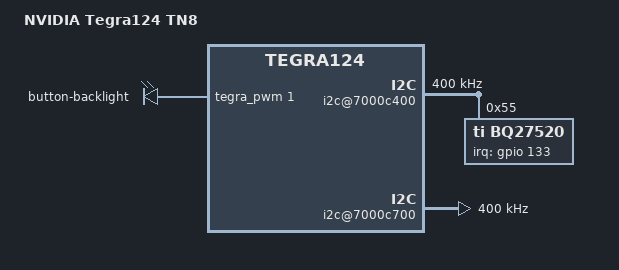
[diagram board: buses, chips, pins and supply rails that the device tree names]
/*
 * arch/arm/boot/dts/tegra124-mocha.dts
 *
 * Copyright (c) 2018, Smoke team.  All rights reserved.
 *
 * This program is free software; you can redistribute it and/or modify
 * it under the terms of the GNU General Public License as published by
 * the Free Software Foundation; either version 2 of the License, or
 * (at your option) any later version.
 *
 * This program is distributed in the hope that it will be useful, but WITHOUT
 * ANY WARRANTY; without even the implied warranty of MERCHANTABILITY or
 * FITNESS FOR A PARTICULAR PURPOSE.  See the GNU General Public License for
 * more details.
 *
 * You should have received a copy of the GNU General Public License along
 * with this program; if not, write to the Free Software Foundation, Inc.,
 * 51 Franklin Street, Fifth Floor, Boston, MA  02110-1301, USA.
 */
/dts-v1/;

#include "tegra124-tn8.dtsi"
#include "tegra124-platforms/tegra124-tn8-emc-e1922-1100-a00.dtsi"
#include "tegra124-platforms/tegra124-mocha-gpio-e1780.dtsi"
#include "tegra124-platforms/tegra124-mocha-keys-e1780.dtsi"
#include "tegra124-platforms/tegra124-mocha-pinmux-e1780.dtsi"
#include "tegra124-platforms/tegra124-mocha-sysedp.dtsi"
#include "tegra124-platforms/tegra124-mocha-power-tree.dtsi"
#include "tegra124-platforms/tegra124-mocha-screen.dtsi"
#include "tegra124-platforms/tegra124-mocha-sdhci.dtsi"
#include "tegra124-platforms/tegra124-mocha-wireless.dtsi"

/ {
	model = "NVIDIA Tegra124 TN8";
	compatible = "nvidia,tn8", "nvidia,tegra124";
	nvidia,dtsfilename = __FILE__;
	nvidia,boardids = "1780:1100:3:A:7","1845:1000:0:A:7";
	#address-cells = <2>;
	#size-cells = <2>;

	chosen {
		bootargs = "tegraid=40.0.0.00.00 vmalloc=256M video=tegrafb console=ttyS0,115200n8 earlyprintk";
		linux,initrd-start = <0x85000000>;
		linux,initrd-end = <0x851bc400>;
	};

	firmware {
		android {
			compatible = "android,firmware";
			hardware = "tn8";
		};
	};

	i2c@7000c400 {
		status = "okay";
		clock-frequency = <400000>;

		bq27520@55 {
			compatible = "ti,bq27520";
			reg = <0x55>;

			interrupt-parent = <&gpio>;
			interrupts = <133 0>;
			ti,fw-lgc-name = "0105_lgc.dffs";
			ti,fw-atl-name = "0205_atl.dffs";
		};
	};

	i2c@7000c700 {
		nvidia,clock-always-on;
		clock-frequency = <400000>;
  		status = "okay";
	};
	
	tegra_pwm: pwm@7000a000 {
		clocks = <&tegra_car 17>;
	};
	
	pwmleds {
		compatible = "pwm-leds";
		button_led {
			label = "button-backlight";
			pwms = <&tegra_pwm 1 10000>;
			max-brightness = <100>;
			max-duty = <50>;
		};
	};
};

